AUTOSAR XML (schema 19-11)
standard types defined: UInt16, UInt8
package /ComponentTypes
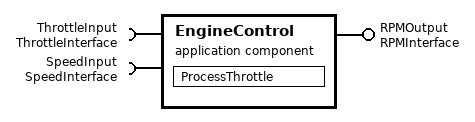
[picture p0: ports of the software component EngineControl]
  application sw component type EngineControl: category=APPLICATION_LAYER
    provide port RPMOutput: provided-interface=RPMInterface
    require port ThrottleInput: required-interface=ThrottleInterface
    require port SpeedInput: required-interface=SpeedInterface
    behavior EngineControlBehavior
      data received event ThrottleDataReceived: start-on-event=ProcessThrottle, data=ThrottleInput.ThrottleValue
      runnable ProcessThrottle: minimum-start-interval=0.01
package /Interfaces
  sender receiver interface RPMInterface
    data RPMValue: type=UInt16
  sender receiver interface SpeedInterface
    data SpeedValue: type=UInt8
package /Systems
  system EngineManagementSystem: category=SYSTEM_EXTRACT
    system mapping SystemMapping
      sw-mappings:
        swc to ecu mapping EngineControlMapping: component=RootComposition.EngineControl, ecu-instance=ECU1
